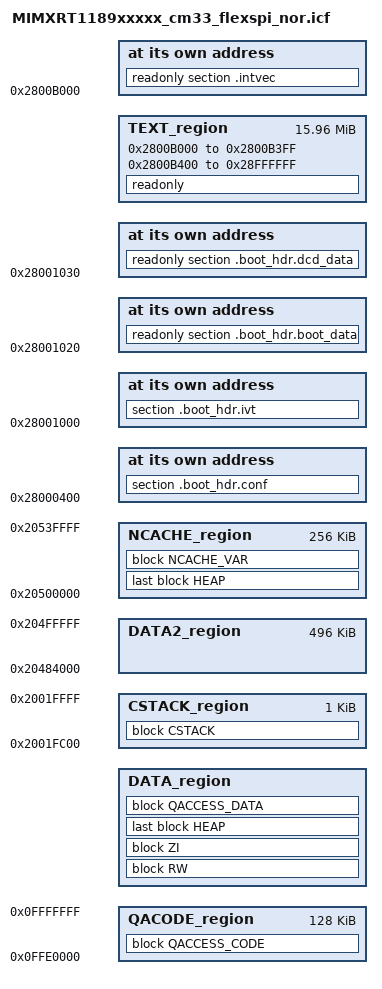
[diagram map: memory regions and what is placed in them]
/*
** ###################################################################
**     Processor:           MIMXRT1189CVM8A_cm33
**     Compiler:            IAR ANSI C/C++ Compiler for ARM
**     Reference manual:    IMXRT1180RM, Rev 0, 03/2021
**     Version:             rev. 0.1, 2021-03-09
**     Build:               b220221
**
**     Abstract:
**         Linker file for the IAR ANSI C/C++ Compiler for ARM
**
**     Copyright 2016 Freescale Semiconductor, Inc.
**     Copyright 2016-2022 NXP
**     All rights reserved.
**
**     SPDX-License-Identifier: BSD-3-Clause
**
**     http:                 www.nxp.com
**     mail:                 support@nxp.com
**
** ###################################################################
*/

define symbol vector_table_size        = 0x00000400;
define symbol ram_vector_table_size    = isdefinedsymbol(__ram_vector_table__) ? vector_table_size : 0;
define symbol app_image_offset         = 0x0000B000;

define symbol m_code_tcm_start         = 0x0FFE0000;
define symbol m_code_tcm_size          = 0x00020000;

define symbol m_system_tcm_start       = 0x20000000;
define symbol m_system_tcm_size        = 0x00020000;

define symbol m_ocram1_start           = 0x20484000;
define symbol m_ocram1_size            = 0x0007C000;

define symbol m_ocram2_start           = 0x20500000;
define symbol m_ocram2_size            = 0x00040000;

define symbol m_flash_start            = 0x28000000;
define symbol m_flash_size             = 0x01000000;

/* code & data allocation */
define symbol m_interrupts_start       = m_flash_start + app_image_offset;
define symbol m_interrupts_end         = m_flash_start + app_image_offset + vector_table_size - 1;

define symbol m_text_start             = m_flash_start + app_image_offset + vector_table_size;
define symbol m_text_end               = m_flash_start + m_flash_size - 1;

define symbol m_qacode_start           = m_code_tcm_start;
define symbol m_qacode_end             = m_code_tcm_start + m_code_tcm_size - 1;

define symbol m_interrupts_ram_start   = m_system_tcm_start;
define symbol m_interrupts_ram_end     = m_system_tcm_start + ram_vector_table_size - 1;

define symbol m_data_start             = m_system_tcm_start + ram_vector_table_size;
define symbol m_data_end               = m_system_tcm_start + m_system_tcm_size -1;

define symbol m_data2_start            = m_ocram1_start;
define symbol m_data2_end              = m_ocram1_start + m_ocram1_size -1;

define symbol m_ncache_start           = m_ocram2_start;
define symbol m_ncache_end             = m_ocram2_start + m_ocram2_size -1;

define exported symbol __NCACHE_REGION_START   = m_ncache_start;
define exported symbol __NCACHE_REGION_SIZE    = m_ncache_end - m_ncache_start + 1;

define exported symbol m_boot_hdr_conf_start = m_flash_start + 0x400;
define symbol m_boot_hdr_ivt_start           = m_flash_start + 0x1000;
define symbol m_boot_hdr_boot_data_start     = m_flash_start + 0x1020;
define symbol m_boot_hdr_dcd_data_start      = m_flash_start + 0x1030;

/* Sizes */
if (isdefinedsymbol(__stack_size__)) {
  define symbol __size_cstack__        = __stack_size__;
} else {
  define symbol __size_cstack__        = 0x0400;
}

if (isdefinedsymbol(__heap_size__)) {
  define symbol __size_heap__          = __heap_size__;
} else {
  define symbol __size_heap__          = 0x0400;
}

define exported symbol __VECTOR_TABLE          = m_interrupts_start;
define exported symbol __VECTOR_RAM            = isdefinedsymbol(__ram_vector_table__) ? m_interrupts_ram_start : m_interrupts_start;
define exported symbol __RAM_VECTOR_TABLE_SIZE = ram_vector_table_size;

define memory mem with size = 4G;
define region TEXT_region = mem:[from m_interrupts_start to m_interrupts_end]
                          | mem:[from m_text_start to m_text_end];
define region QACODE_region = mem:[from m_qacode_start to m_qacode_end];
define region DATA_region = mem:[from m_data_start to m_data_end-__size_cstack__];
define region DATA2_region = mem:[from m_data2_start to m_data2_end];
define region CSTACK_region = mem:[from m_data_end-__size_cstack__+1 to m_data_end];
define region NCACHE_region = mem:[from m_ncache_start to m_ncache_end];

define block RW        { readwrite };
define block ZI        { zi };
define block CSTACK    with alignment = 8, size = __size_cstack__   { };
define block HEAP      with alignment = 8, size = __size_heap__     { };
define block NCACHE_VAR    { section NonCacheable , section NonCacheable.init };
define block QACCESS_CODE  { section CodeQuickAccess };
define block QACCESS_DATA  { section DataQuickAccess };

initialize by copy { readwrite, section .textrw, section CodeQuickAccess, section DataQuickAccess,
  object flexspi_nor_flash_ops.o,
  object fsl_flexspi.o
};
do not initialize  { section .noinit };

place at address mem: m_interrupts_start    { readonly section .intvec };
place at address mem: m_boot_hdr_conf_start { section .boot_hdr.conf };
place at address mem: m_boot_hdr_ivt_start { section .boot_hdr.ivt };
place at address mem: m_boot_hdr_boot_data_start { readonly section .boot_hdr.boot_data };
place at address mem: m_boot_hdr_dcd_data_start { readonly section .boot_hdr.dcd_data };

keep{ section .boot_hdr.conf, section .boot_hdr.ivt, section .boot_hdr.boot_data, section .boot_hdr.dcd_data };

place in TEXT_region                        { readonly };
place in DATA_region                        { block RW };
place in DATA_region                        { block ZI };
if (isdefinedsymbol(__heap_noncacheable__)) {
  place in NCACHE_region                    { last block HEAP };
} else {
  place in DATA_region                      { last block HEAP };
}
place in CSTACK_region                      { block CSTACK };
place in NCACHE_region                      { block NCACHE_VAR };
place in QACODE_region                      { block QACCESS_CODE };
place in DATA_region                        { block QACCESS_DATA };
